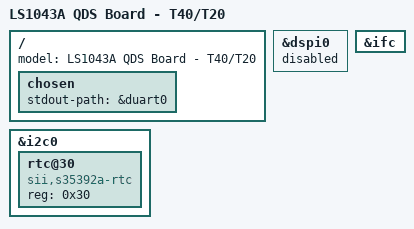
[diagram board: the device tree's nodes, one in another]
// SPDX-License-Identifier: GPL-2.0+ OR X11
/*
 * Device Tree file for Freescale Layerscape-1043A family SoC.
 *
 * Copyright (C) 2015, Freescale Semiconductor
 */

/dts-v1/;
#include "fsl-ls1043a-qds.dtsi"

/ {
	model = "LS1043A QDS Board - T40/T20";
       chosen {
               stdout-path = &duart0;
       };
};

&dspi0 {
	status = "disabled";
};

&i2c0 {
	/delete-node/ pca9547@77;

	rtc@30 {
		compatible = "sii,s35392a-rtc";
		reg = <0x30>;
	};
};

&ifc {
	/delete-node/ nand@1,0;
	/delete-node/ board-control@2,0;
};
